# STM8AL3166 register map
Vendor: STMicroelectronics; Series: STM8L/STM8AL, medium density; File version: 1.0
CPU: other r1p0, big endian, no MPU, no FPU, 4 interrupt priority bits
Registers are 8-bit, read-write, reset 0x0 unless marked. A register's access mark holds for its fields unless they carry their own. Offsets are from the block's base; [hi:lo] are bit positions; lines under a group give offsets from that group; {n}, {i} and the like mark numbered series.

## REMAP
Base 0x0000509E
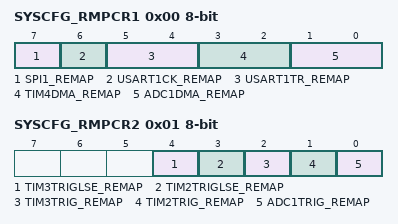
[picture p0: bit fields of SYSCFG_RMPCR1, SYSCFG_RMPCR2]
0x00 SYSCFG_RMPCR1 — Remapping register 1
  [7] SPI1_REMAP, [6] USART1CK_REMAP, [5:4] USART1TR_REMAP, [3:2] TIM4DMA_REMAP, [1:0] ADC1DMA_REMAP
0x01 SYSCFG_RMPCR2 — Remapping register 2
  [4] TIM3TRIGLSE_REMAP, [3] TIM2TRIGLSE_REMAP, [2] TIM3TRIG_REMAP, [1] TIM2TRIG_REMAP, [0] ADC1TRIG_REMAP

## RI
Base 0x00005431
0x00 ICR1 — Timer input capture routing register 1
  [4:0] IC2CS
0x01 ICR2 — Timer input capture routing register 2
  [4:0] IC3CS
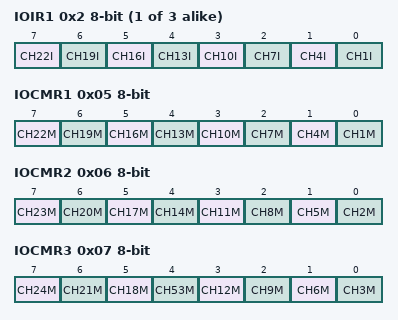
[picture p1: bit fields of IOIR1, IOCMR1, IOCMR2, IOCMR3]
{0x1+i} IOIR{i} (i=1..3) — I/O input register {i}
  [7] CH{i+21}I, [6] CH{i+18}I, [5] CH{i+15}I, [4] CH{i+12}I, [3] CH{i+9}I, [2] CH{i+6}I, [1] CH{i+3}I, [0] CH{i}I
0x05 IOCMR1 — I/O control mode register 1
  [7] CH22M, [6] CH19M, [5] CH16M, [4] CH13M, [3] CH10M, [2] CH7M, [1] CH4M, [0] CH1M
0x06 IOCMR2 — I/O control mode register 2
  [7] CH23M, [6] CH20M, [5] CH17M, [4] CH14M, [3] CH11M, [2] CH8M, [1] CH5M, [0] CH2M
0x07 IOCMR3 — I/O control mode register 3
  [7] CH24M, [6] CH21M, [5] CH18M, [4] CH53M, [3] CH12M, [2] CH9M, [1] CH6M, [0] CH3M
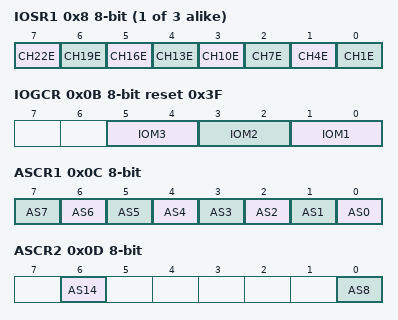
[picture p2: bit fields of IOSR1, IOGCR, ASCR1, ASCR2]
{0x7+i} IOSR{i} (i=1..3) — I/O switch register {i}
  [7] CH{i+21}E, [6] CH{i+18}E, [5] CH{i+15}E, [4] CH{i+12}E, [3] CH{i+9}E, [2] CH{i+6}E, [1] CH{i+3}E, [0] CH{i}E
0x0B IOGCR reset 0x3F — I/O group control register
  [5:4] IOM3, [3:2] IOM2, [1:0] IOM1
0x0C ASCR1 — Analog switch register 1
  [n] AS{n} (n=0..7)
0x0D ASCR2 — Analog switch register 2
  [6] AS14, [0] AS8
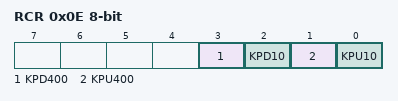
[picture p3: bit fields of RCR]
0x0E RCR — Resistor control register 1
  [3] KPD400, [2] KPD10, [1] KPU400, [0] KPU10

## RST
Base 0x000050B0
0x00 CR — Reset control register
  [7:0] RSTPIN_KEY
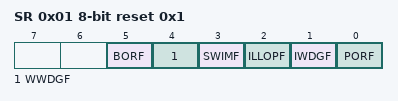
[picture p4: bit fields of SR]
0x01 SR reset 0x1 — Reset status register
  [5] BORF, [4] WWDGF, [3] SWIMF, [2] ILLOPF, [1] IWDGF, [0] PORF

## RTC
Base 0x00005140
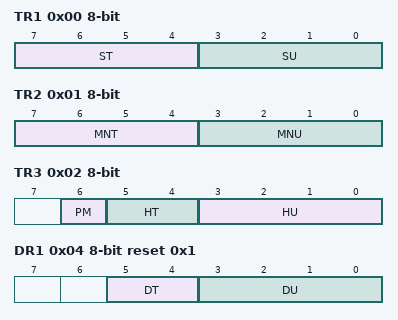
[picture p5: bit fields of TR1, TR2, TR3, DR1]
0x00 TR1 — Time register 1
  [7:4] ST, [3:0] SU
0x01 TR2 — Time register 2
  [7:4] MNT, [3:0] MNU
0x02 TR3 — Time register 3
  [6] PM, [5:4] HT, [3:0] HU
0x04 DR1 reset 0x1 — Date register 1
  [5:4] DT, [3:0] DU
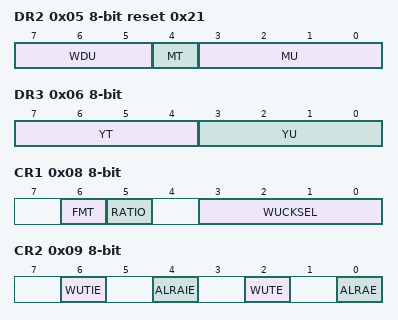
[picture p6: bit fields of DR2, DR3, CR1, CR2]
0x05 DR2 reset 0x21 — Date register 2
  [7:5] WDU, [4] MT, [3:0] MU
0x06 DR3 — Date register 3
  [7:4] YT, [3:0] YU
0x08 CR1 — Control register 1
  [6] FMT, [5] RATIO, [3:0] WUCKSEL
0x09 CR2 — Control register 2
  [6] WUTIE, [4] ALRAIE, [2] WUTE, [0] ALRAE
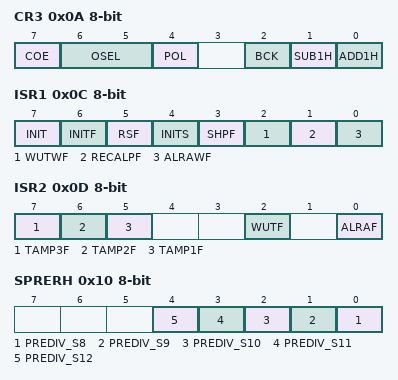
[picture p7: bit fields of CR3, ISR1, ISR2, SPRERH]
0x0A CR3 — Control register 3
  [7] COE, [6:5] OSEL, [4] POL, [2] BCK, [1] SUB1H, [0] ADD1H
0x0C ISR1 — Initialization and status register 1
  [7] INIT, [6] INITF, [5] RSF, [4] INITS, [3] SHPF, [2] WUTWF, [1] RECALPF, [0] ALRAWF
0x0D ISR2 — Initialization and Status register 2
  [7] TAMP3F, [6] TAMP2F, [5] TAMP1F, [2] WUTF, [0] ALRAF
0x10 SPRERH — Synchronous prescaler register high
  [n-8] PREDIV_S{n} (n=8..12)
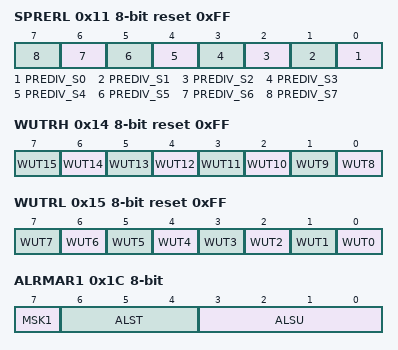
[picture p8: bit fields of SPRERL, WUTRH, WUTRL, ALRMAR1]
0x11 SPRERL reset 0xFF — Synchronous prescaler register low
  [n] PREDIV_S{n} (n=0..7)
0x12 APRER reset 0x7F — Asynchronous prescaler register
  [6:0] PREDIV_A
0x14 WUTRH reset 0xFF — Wakeup timer register high
  [n-8] WUT{n} (n=8..15)
0x15 WUTRL reset 0xFF — Wakeup timer register low
  [n] WUT{n} (n=0..7)
0x19 WPR — Write protection register
  [7:0] KEY
0x1C ALRMAR1 — Alarm A register 1
  [7] MSK1, [6:4] ALST, [3:0] ALSU
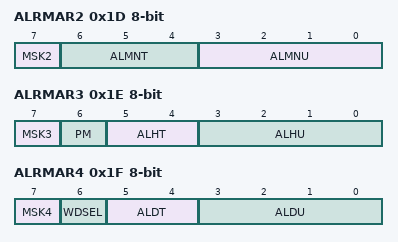
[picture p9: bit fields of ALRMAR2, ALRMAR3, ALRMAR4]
0x1D ALRMAR2 — Alarm A register 2
  [7] MSK2, [6:4] ALMNT, [3:0] ALMNU
0x1E ALRMAR3 — Alarm A register 3
  [7] MSK3, [6] PM, [5:4] ALHT, [3:0] ALHU
0x1F ALRMAR4 — Alarm A register 4
  [7] MSK4, [6] WDSEL, [5:4] ALDT, [3:0] ALDU

## SPI1
Base 0x00005200
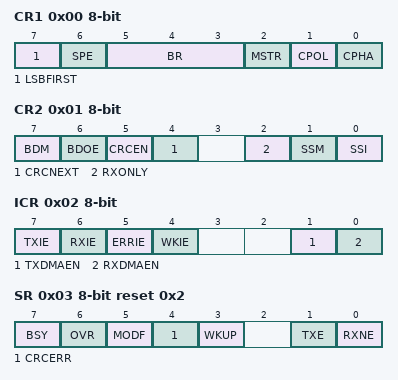
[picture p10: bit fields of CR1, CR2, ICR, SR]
0x00 CR1 — SPI1 control register 1
  [7] LSBFIRST, [6] SPE, [5:3] BR, [2] MSTR, [1] CPOL, [0] CPHA
0x01 CR2 — SPI1 control register 2
  [7] BDM, [6] BDOE, [5] CRCEN, [4] CRCNEXT, [2] RXONLY, [1] SSM, [0] SSI
0x02 ICR — SPI1 interrupt control register
  [7] TXIE, [6] RXIE, [5] ERRIE, [4] WKIE, [1] TXDMAEN, [0] RXDMAEN
0x03 SR reset 0x2 — SPI1 status register
  [7] BSY, [6] OVR, [5] MODF, [4] CRCERR, [3] WKUP, [1] TXE, [0] RXNE
0x04 DR — SPI1 data register
0x05 CRCPR reset 0x7 — SPI1 CRC polynomial register
  [7:0] CRCPOLY
0x06 RXCRCR — SPI1 Rx CRC register
  [7:0] RXCRC
0x07 TXCRCR — SPI1 Tx CRC register
  [6:0] TXCRC
